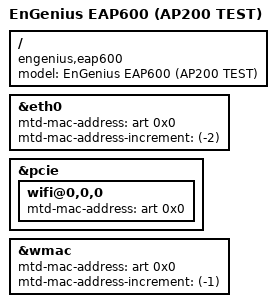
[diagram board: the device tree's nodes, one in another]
// SPDX-License-Identifier: GPL-2.0-or-later OR MIT

#include "ar9344_engenius_exx600.dtsi"

/ {
	model = "EnGenius EAP600 (AP200 TEST)";
	compatible = "engenius,eap600", "qca,ar9344";
};

&eth0 {
	mtd-mac-address = <&art 0x0>;
	mtd-mac-address-increment = <(-2)>;
};

&pcie {
	wifi@0,0,0 {
		mtd-mac-address = <&art 0x0>;
	};
};

&wmac {
	mtd-mac-address = <&art 0x0>;
	mtd-mac-address-increment = <(-1)>;
};
